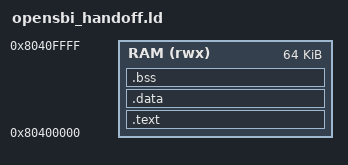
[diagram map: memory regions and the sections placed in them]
OUTPUT_ARCH(riscv)
ENTRY(_start)
MEMORY { RAM (rwx) : ORIGIN = 0x80400000, LENGTH = 64K }
SECTIONS {
    .text : { *(.text.start) *(.text*) *(.rodata*) } > RAM
    .data : { *(.data*) } > RAM
    .bss (NOLOAD) : { *(.bss*) } > RAM
}
